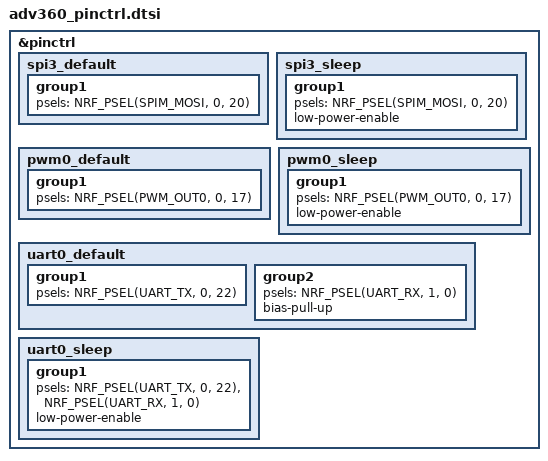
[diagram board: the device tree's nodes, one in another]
/*
 * Copyright (c) 2023 The ZMK Contributors
 * SPDX-License-Identifier: MIT
 */

&pinctrl {
	spi3_default: spi3_default {
		group1 {
			psels = <NRF_PSEL(SPIM_MOSI, 0, 20)>;
		};
	};

	spi3_sleep: spi3_sleep {
		group1 {
			psels = <NRF_PSEL(SPIM_MOSI, 0, 20)>;
			low-power-enable;
		};
	};

	pwm0_default: pwm0_default {
		group1 {
			psels = <NRF_PSEL(PWM_OUT0, 0, 17)>;
		};
	};

	pwm0_sleep: pwm0_sleep {
		group1 {
			psels = <NRF_PSEL(PWM_OUT0, 0, 17)>;
			low-power-enable;
		};
	};

	uart0_default: uart0_default {
		group1 {
			psels = <NRF_PSEL(UART_TX, 0, 22)>;
		};
		group2 {
			psels = <NRF_PSEL(UART_RX, 1, 0)>;
			bias-pull-up;
		};
	};

	uart0_sleep: uart0_sleep {
		group1 {
			psels = <NRF_PSEL(UART_TX, 0, 22)>,
				<NRF_PSEL(UART_RX, 1, 0)>;
			low-power-enable;
		};
	};
};
